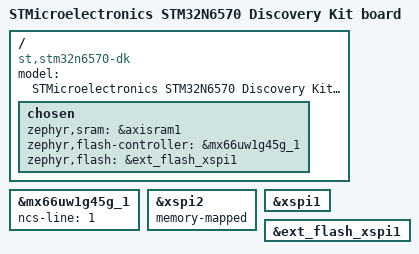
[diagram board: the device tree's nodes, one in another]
/*
 * Copyright (c) 2025 STMicroelectronics
 *
 * SPDX-License-Identifier: Apache-2.0
 */

/dts-v1/;
#include "stm32n6570_dk_common.dtsi"

/ {
	model = "STMicroelectronics STM32N6570 Discovery Kit board";
	compatible = "st,stm32n6570-dk";

	chosen {
		zephyr,sram = &axisram1;
		zephyr,flash-controller = &mx66uw1g45g_1;
		zephyr,flash = &ext_flash_xspi1;
	};
};

&mx66uw1g45g_1{
	status = "okay";
	ncs-line = <1>;
};

&xspi2 {
	/* Required to be able to retrieve FLASH_BASE_ADDRESS */
	status = "okay";
	memory-mapped;
};

&xspi1 {
	status = "okay";
};

&ext_flash_xspi1{
	status = "okay";
	#include "partitions.dtsi"
};
